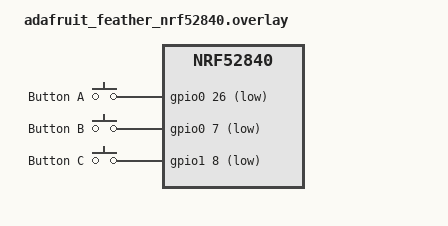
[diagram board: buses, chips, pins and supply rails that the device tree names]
/*
 * Copyright (c) 2025 Stefan Schmidt <kontakt@stefanschmidt-embedded.de>
 *
 * SPDX-License-Identifier: Apache-2.0
 */

/ {
	buttons {
        compatible = "gpio-keys";
        buttonA: button_A {
            gpios = <&gpio0 26 (GPIO_PULL_UP | GPIO_ACTIVE_LOW)>;
            label = "Button A";
            zephyr,code = <INPUT_KEY_1>;
        };
        buttonB: button_B {
            gpios = <&gpio0 7 (GPIO_ACTIVE_LOW)>;
            label = "Button B";
            zephyr,code = <INPUT_KEY_2>;
        };
        buttonC: button_C {
            gpios = <&gpio1 8 (GPIO_PULL_UP | GPIO_ACTIVE_LOW)>;
            label = "Button C";
            zephyr,code = <INPUT_KEY_3>;
        };
    };
};
